# girlsoc register map
Vendor: luna-soc
Registers are 8-bit, read-write, reset 0x0 unless marked. A register's access mark holds for its fields unless they carry their own. Offsets are from the block's base; [hi:lo] are bit positions; <NAME> marks a mode.

## spiflash_ctrl
Base 0xF0000100
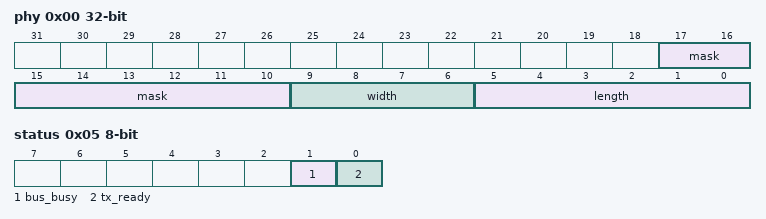
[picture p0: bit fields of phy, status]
0x00 phy 32-bit — A CSR register. Parameters ---------- fields : :class:`dict` or :class:`list` or :class:`Field` Collection of register fields. If ``None`` (default), a dict is populated from Python :term:`variable annotations <python:variable annotations>`. ``fields`` is used to create a :class:`FieldActionMap`, :class:`FieldActionArray`, or :class:`FieldAction`, depending on its type (dict, list, or Field). Interface attributes -------------------- element : :class:`Element` Interface between this register and a CSR bus primitive. Attributes ---------- field : :class:`FieldActionMap` or :class:`FieldActionArray` or :class:`FieldAction` Collection of field instances. f : :class:`FieldActionMap` or :class:`FieldActionArray` or :class:`FieldAction` Shorthand for :attr:`Register.field`. Raises ------ :exc:`TypeError` If ``fields`` is neither ``None``, a :class:`dict`, a :class:`list`, or a :class:`Field`. :exc:`ValueError` If ``fields`` is not ``None`` and at least one variable annotation is a :class:`Field`. :exc:`ValueError` If ``element.access`` is not readable and at least one field is readable. :exc:`ValueError` If ``element.access`` is not writable and at least one field is writable.
  [17:10] mask, [9:6] width, [5:0] length
0x04 cs — A CSR register. Parameters ---------- fields : :class:`dict` or :class:`list` or :class:`Field` Collection of register fields. If ``None`` (default), a dict is populated from Python :term:`variable annotations <python:variable annotations>`. ``fields`` is used to create a :class:`FieldActionMap`, :class:`FieldActionArray`, or :class:`FieldAction`, depending on its type (dict, list, or Field). Interface attributes -------------------- element : :class:`Element` Interface between this register and a CSR bus primitive. Attributes ---------- field : :class:`FieldActionMap` or :class:`FieldActionArray` or :class:`FieldAction` Collection of field instances. f : :class:`FieldActionMap` or :class:`FieldActionArray` or :class:`FieldAction` Shorthand for :attr:`Register.field`. Raises ------ :exc:`TypeError` If ``fields`` is neither ``None``, a :class:`dict`, a :class:`list`, or a :class:`Field`. :exc:`ValueError` If ``fields`` is not ``None`` and at least one variable annotation is a :class:`Field`. :exc:`ValueError` If ``element.access`` is not readable and at least one field is readable. :exc:`ValueError` If ``element.access`` is not writable and at least one field is writable.
  [0] select wo
0x05 status — A CSR register. Parameters ---------- fields : :class:`dict` or :class:`list` or :class:`Field` Collection of register fields. If ``None`` (default), a dict is populated from Python :term:`variable annotations <python:variable annotations>`. ``fields`` is used to create a :class:`FieldActionMap`, :class:`FieldActionArray`, or :class:`FieldAction`, depending on its type (dict, list, or Field). Interface attributes -------------------- element : :class:`Element` Interface between this register and a CSR bus primitive. Attributes ---------- field : :class:`FieldActionMap` or :class:`FieldActionArray` or :class:`FieldAction` Collection of field instances. f : :class:`FieldActionMap` or :class:`FieldActionArray` or :class:`FieldAction` Shorthand for :attr:`Register.field`. Raises ------ :exc:`TypeError` If ``fields`` is neither ``None``, a :class:`dict`, a :class:`list`, or a :class:`Field`. :exc:`ValueError` If ``fields`` is not ``None`` and at least one variable annotation is a :class:`Field`. :exc:`ValueError` If ``element.access`` is not readable and at least one field is readable. :exc:`ValueError` If ``element.access`` is not writable and at least one field is writable.
  [1] bus_busy ro, [0] tx_ready ro
0x08 data 32-bit — A CSR register. Parameters ---------- fields : :class:`dict` or :class:`list` or :class:`Field` Collection of register fields. If ``None`` (default), a dict is populated from Python :term:`variable annotations <python:variable annotations>`. ``fields`` is used to create a :class:`FieldActionMap`, :class:`FieldActionArray`, or :class:`FieldAction`, depending on its type (dict, list, or Field). Interface attributes -------------------- element : :class:`Element` Interface between this register and a CSR bus primitive. Attributes ---------- field : :class:`FieldActionMap` or :class:`FieldActionArray` or :class:`FieldAction` Collection of field instances. f : :class:`FieldActionMap` or :class:`FieldActionArray` or :class:`FieldAction` Shorthand for :attr:`Register.field`. Raises ------ :exc:`TypeError` If ``fields`` is neither ``None``, a :class:`dict`, a :class:`list`, or a :class:`Field`. :exc:`ValueError` If ``fields`` is not ``None`` and at least one variable annotation is a :class:`Field`. :exc:`ValueError` If ``element.access`` is not readable and at least one field is readable. :exc:`ValueError` If ``element.access`` is not writable and at least one field is writable.
  [31:0] tx wo
